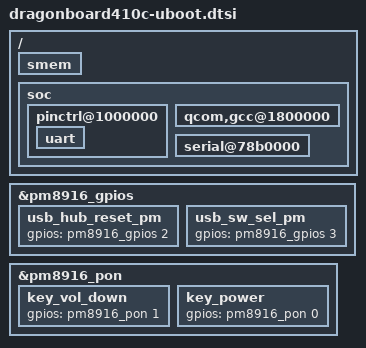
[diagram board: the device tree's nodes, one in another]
// SPDX-License-Identifier: GPL-2.0+
/*
 * U-Boot addition to handle Dragonboard 410c pins
 *
 * (C) Copyright 2015 Mateusz Kulikowski <mateusz.kulikowski@gmail.com>
 */

/ {

	smem {
		u-boot,dm-all;
	};

	soc {
		u-boot,dm-all;

		pinctrl@1000000 {
			u-boot,dm-all;

			uart {
				u-boot,dm-all;
			};
		};

		qcom,gcc@1800000 {
			u-boot,dm-all;
		};

		serial@78b0000 {
			u-boot,dm-all;
		};
	};
};


&pm8916_gpios {
	usb_hub_reset_pm {
		gpios = <&pm8916_gpios 2 0>;
	};

	usb_sw_sel_pm {
		gpios = <&pm8916_gpios 3 0>;
	};
};


&pm8916_pon {
	key_vol_down {
		gpios = <&pm8916_pon 1 0>;
	};

	key_power {
		gpios = <&pm8916_pon 0 0>;
	};
};
